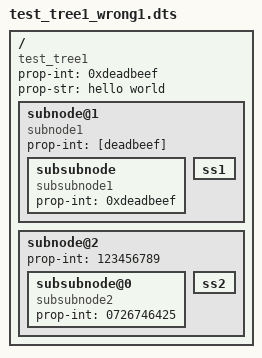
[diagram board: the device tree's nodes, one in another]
/dts-v1/;

/memreserve/ 123456789 010000;

/ {
	compatible = "test_tree1";
	prop-int = <0xdeadbeef>;
	prop-str = "hello world";

	subnode@1 {
		compatible = "subnode1";
		prop-int = [deadbeef];

		subsubnode {
			compatible = "subsubnode1", "subsubnode";
			prop-int = <0xdeadbeef>;
		};

		ss1 {
		};
	};

	subnode@2 {
		linux,phandle = <0x2000>;
		prop-int = <123456789>;

		subsubnode@0 {
			phandle = <0x2001>;
			compatible = "subsubnode2", "subsubnode";
			prop-int = <0726746425>;
		};

		ss2 {
		};
	};
};
